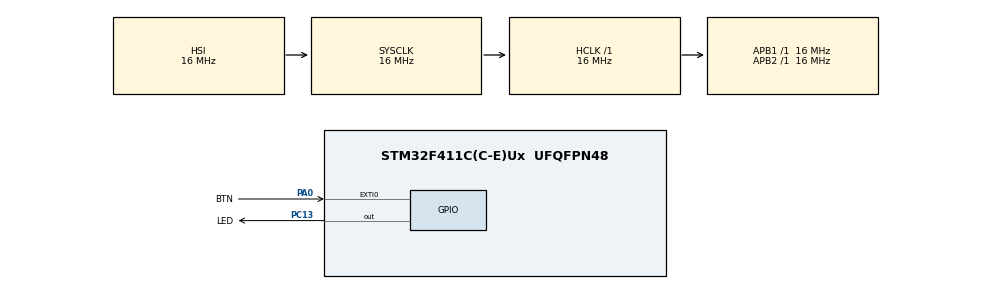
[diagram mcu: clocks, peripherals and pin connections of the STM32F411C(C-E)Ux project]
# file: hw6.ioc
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Mcu.Family=STM32F4
Mcu.Name=STM32F411C(C-E)Ux
Mcu.Package=UFQFPN48
NVIC.EXTI0_IRQn=true\:0\:0\:false\:false\:true\:true\:true\:true
NVIC.PriorityGroup=NVIC_PRIORITYGROUP_4
PA0-WKUP.GPIO_Label=BTN
PA0-WKUP.GPIO_ModeDefaultEXTI=GPIO_MODE_IT_FALLING
PA0-WKUP.Signal=GPXTI0
PC13-ANTI_TAMP.GPIO_Label=LED
PC13-ANTI_TAMP.Signal=GPIO_Output
ProjectManager.HeapSize=0x200
ProjectManager.StackSize=0x400
ProjectManager.TargetToolchain=Makefile
RCC.AHBFreq_Value=16000000
RCC.APB1Freq_Value=16000000
RCC.APB2Freq_Value=16000000
RCC.CortexFreq_Value=16000000
RCC.HSE_VALUE=25000000
RCC.HSI_VALUE=16000000
RCC.LSE_VALUE=32768
RCC.SYSCLKFreq_VALUE=16000000
RCC.VCOOutputFreq_Value=192000000
board=custom

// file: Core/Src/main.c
/* USER CODE BEGIN Header */
/**
  ******************************************************************************
  * @file           : main.c
  * @brief          : Main program body
  ******************************************************************************
  * @attention
  *
  * Copyright (c) 2026 STMicroelectronics.
  * All rights reserved.
  *
  * This software is licensed under terms that can be found in the LICENSE file
  * in the root directory of this software component.
  * If no LICENSE file comes with this software, it is provided AS-IS.
  *
  ******************************************************************************
  */
/* USER CODE END Header */
#include "main.h"
#include "gpio.h"

/* USER CODE BEGIN PTD */
typedef enum {
  MODE_RUN,
  MODE_SLEEP,
  MODE_STOP
} mode_t;
/* USER CODE END PTD */

/* USER CODE BEGIN PM */
#define BTN_TICKS 100
/* USER CODE END PM */

/* USER CODE BEGIN PV */
volatile uint32_t pressed = 0;
/* USER CODE END PV */

void SystemClock_Config(void);

/* USER CODE BEGIN 0 */
mode_t next_mode = MODE_SLEEP;
/* USER CODE END 0 */

int main(void)
{

  /* MCU Configuration--------------------------------------------------------*/

  /* Reset of all peripherals, Initializes the Flash interface and the Systick. */
  HAL_Init();

  /* Configure the system clock */
  SystemClock_Config();

  /* Initialize all configured peripherals */
  MX_GPIO_Init();

  /* Infinite loop */
  /* USER CODE BEGIN WHILE */
  uint32_t tick_led = 0;
  // uint32_t tick_btn = 0;
  uint32_t blink_period = 200;

  if((HAL_GetTick() - tick_led) > 200) {
    LED_GPIO_Port->BSRR = (uint32_t)LED_Pin;
    tick_led = HAL_GetTick();
  }
  if((HAL_GetTick() - tick_led) > 400) {
    LED_GPIO_Port->BSRR = (uint32_t)LED_Pin << 16;
    tick_led = HAL_GetTick();
  }

  while (1)
  {
    uint32_t tick = HAL_GetTick();

      if((tick - tick_led) > blink_period) {
        LED_GPIO_Port->BSRR = (uint32_t)LED_Pin << ((LED_GPIO_Port->ODR & LED_Pin) ? 16 : 0);
        tick_led = tick;
      }

    if(pressed) {
      HAL_Delay(BTN_TICKS); // filter the bounce
      LED_GPIO_Port->BSRR = (uint32_t)LED_Pin;
      HAL_SuspendTick(); // disable SysTick interrupt
      SCB->ICSR = SCB_ICSR_PENDSTCLR_Msk;  // flush SysTick interrupt
      switch (next_mode) {
        case MODE_SLEEP:
          CLEAR_BIT(SCB->SCR, ((uint32_t)SCB_SCR_SLEEPDEEP_Msk));
          next_mode = MODE_STOP;
          __WFI();
          break;
        case MODE_STOP:
          SET_BIT(SCB->SCR, ((uint32_t)SCB_SCR_SLEEPDEEP_Msk));
          CLEAR_BIT(PWR->CR, PWR_CR_PDDS);
          next_mode = MODE_SLEEP;
          __WFI();
          SystemClock_Config(); // restore clock settings
          break;
        case MODE_RUN:
          break;
      }
      HAL_ResumeTick();
      pressed = 0;
    }
    /* USER CODE END WHILE */
  }
}

void SystemClock_Config(void)
{
  RCC_OscInitTypeDef RCC_OscInitStruct = {0};
  RCC_ClkInitTypeDef RCC_ClkInitStruct = {0};

  /** Configure the main internal regulator output voltage
  */
  __HAL_RCC_PWR_CLK_ENABLE();
  __HAL_PWR_VOLTAGESCALING_CONFIG(PWR_REGULATOR_VOLTAGE_SCALE1);

  /** Initializes the RCC Oscillators according to the specified parameters
  * in the RCC_OscInitTypeDef structure.
  */
  RCC_OscInitStruct.OscillatorType = RCC_OSCILLATORTYPE_HSI;
  RCC_OscInitStruct.HSIState = RCC_HSI_ON;
  RCC_OscInitStruct.HSICalibrationValue = RCC_HSICALIBRATION_DEFAULT;
  RCC_OscInitStruct.PLL.PLLState = RCC_PLL_NONE;
  if (HAL_RCC_OscConfig(&RCC_OscInitStruct) != HAL_OK)
  {
    Error_Handler();
  }

  /** Initializes the CPU, AHB and APB buses clocks
  */
  RCC_ClkInitStruct.ClockType = RCC_CLOCKTYPE_HCLK|RCC_CLOCKTYPE_SYSCLK
                              |RCC_CLOCKTYPE_PCLK1|RCC_CLOCKTYPE_PCLK2;
  RCC_ClkInitStruct.SYSCLKSource = RCC_SYSCLKSOURCE_HSI;
  RCC_ClkInitStruct.AHBCLKDivider = RCC_SYSCLK_DIV1;
  RCC_ClkInitStruct.APB1CLKDivider = RCC_HCLK_DIV1;
  RCC_ClkInitStruct.APB2CLKDivider = RCC_HCLK_DIV1;

  if (HAL_RCC_ClockConfig(&RCC_ClkInitStruct, FLASH_LATENCY_0) != HAL_OK)
  {
    Error_Handler();
  }
}

/* USER CODE BEGIN 4 */
void HAL_GPIO_EXTI_Callback(uint16_t GPIO_Pin) {
//  if(GPIO_Pin == BTN_Pin) {
    pressed = 1;
//  }
}
/* USER CODE END 4 */

void Error_Handler(void)
{
  __disable_irq();
  while (1)
  {
  }
}
